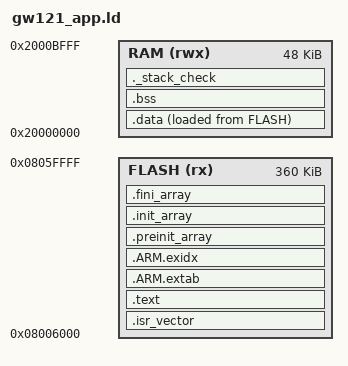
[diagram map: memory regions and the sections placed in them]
/* The 121GW's STM32L152ZD with its stock bootloader kept: our firmware goes
   where the bootloader jumps, 0x08006000, as EEVBlog.bin does. 384 KB flash
   less the bootloader's 24 KB; 48 KB RAM. The data EEPROM (0x08080000, the
   calibration) isn't touched. */
ENTRY(Reset_Handler)

MEMORY
{
  FLASH (rx)  : ORIGIN = 0x08006000, LENGTH = 360K
  RAM   (rwx) : ORIGIN = 0x20000000, LENGTH = 48K
}

_estack = ORIGIN(RAM) + LENGTH(RAM);

SECTIONS
{
  .isr_vector : { KEEP(*(.isr_vector)) } > FLASH

  .text : {
    *(.text*) *(.rodata*)
    KEEP(*(.init)) KEEP(*(.fini))
    . = ALIGN(4);
  } > FLASH

  .ARM.extab : { *(.ARM.extab* .gnu.linkonce.armextab.*) } > FLASH
  .ARM.exidx : { __exidx_start = .; *(.ARM.exidx*) __exidx_end = .; } > FLASH

  .preinit_array : { PROVIDE_HIDDEN(__preinit_array_start = .); KEEP(*(.preinit_array*)) PROVIDE_HIDDEN(__preinit_array_end = .); } > FLASH
  .init_array : { PROVIDE_HIDDEN(__init_array_start = .); KEEP(*(SORT(.init_array.*))) KEEP(*(.init_array*)) PROVIDE_HIDDEN(__init_array_end = .); } > FLASH
  .fini_array : { PROVIDE_HIDDEN(__fini_array_start = .); KEEP(*(.fini_array*)) PROVIDE_HIDDEN(__fini_array_end = .); } > FLASH

  _sidata = LOADADDR(.data);
  .data : { . = ALIGN(4); _sdata = .; *(.data*) . = ALIGN(4); _edata = .; } > RAM AT > FLASH

  .bss (NOLOAD) : { . = ALIGN(4); _sbss = .; *(.bss*) *(COMMON) . = ALIGN(4); _ebss = .; } > RAM

  /* At least 4 KB left for the stack. */
  ._stack_check (NOLOAD) : { . = ALIGN(8); . = . + 4096; } > RAM

}
